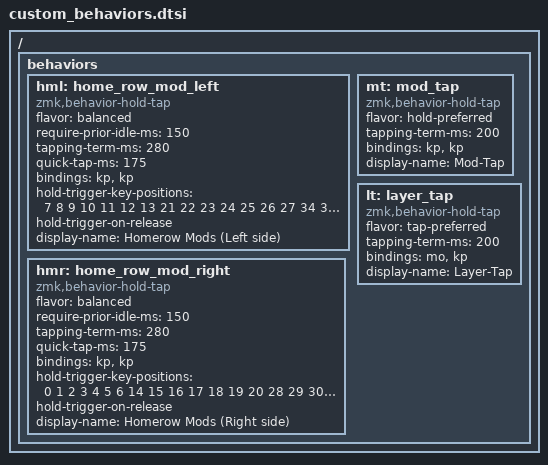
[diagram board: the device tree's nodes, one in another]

#include <dt-bindings/zmk/behaviors.h>

// ----------------------------------------------------------------------------------------------------------------
// |   0  |   1  |   2  |   3  |   4  |   5  |   6  |            |   7  |   8  |   9  |  10  |  11  |  12  |  13  |
// |  14  |  15  |  16  |  17  |  18  |  19  |  20  |            |  21  |  22  |  23  |  24  |  25  |  26  |  27  |
// |  28  |  29  |  30  |  31  |  32  |  33  |                          |  34  |  35  |  36  |  37  |  38  |  39  |
//
//                             |  40  |  41  |  42  |            |  43  |  44  |  45  |
// ----------------------------------------------------------------------------------------------------------------


/ {
    behaviors {

        hml: home_row_mod_left {
            compatible = "zmk,behavior-hold-tap";
            #binding-cells = <2>;
            flavor = "balanced";
            require-prior-idle-ms = <150>;
            tapping-term-ms = <280>;
            quick-tap-ms = <175>;
            bindings = <&kp>, <&kp>;
            hold-trigger-key-positions = < 7 8 9 10 11 12 13   21 22 23 24 25 26 27   34 35 36 37 38 39   43 44 45 >;
            hold-trigger-on-release;
            display-name = "Homerow Mods (Left side)";
        };


        hmr: home_row_mod_right {
            compatible = "zmk,behavior-hold-tap";
            #binding-cells = <2>;
            flavor = "balanced";
            require-prior-idle-ms = <150>;
            tapping-term-ms = <280>;
            quick-tap-ms = <175>;
            bindings = <&kp>, <&kp>;
            hold-trigger-key-positions = < 0 1 2 3 4 5 6   14 15 16 17 18 19 20   28 29 30 31 32 33   40 41 42 >;
            hold-trigger-on-release;
            display-name = "Homerow Mods (Right side)";
        };


        mt: mod_tap {
            compatible = "zmk,behavior-hold-tap";
            #binding-cells = <2>;
            flavor = "hold-preferred";
            tapping-term-ms = <200>;
            bindings = <&kp>, <&kp>;
            display-name = "Mod-Tap";
        };     


        lt: layer_tap {
            compatible = "zmk,behavior-hold-tap";
            #binding-cells = <2>;
            flavor = "tap-preferred";
            tapping-term-ms = <200>;
            bindings = <&mo>, <&kp>;
            display-name = "Layer-Tap";
        };           
        
    };
};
